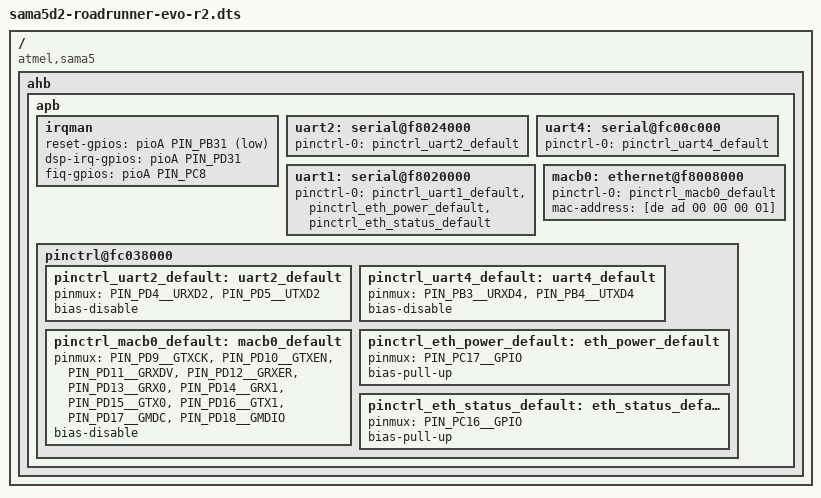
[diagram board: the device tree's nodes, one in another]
/dts-v1/;
/plugin/;

#include "../sama5d2-pinfunc.h"
#include <dt-bindings/gpio/gpio.h>

/ {
    fragment@011111 {
        target-path = "/";
        __overlay__ {
            compatible = "atmel,sama5", "atmel,sama5d2", "atmel,sama5d2-evo-r2";
            ahb {
                apb {
                    irqman: irqman {
                        reset-gpios     = <&pioA PIN_PB31 GPIO_ACTIVE_LOW>;  /* Reset on R2 is ACTIVE_LOW */
                        dsp-irq-gpios	= <&pioA PIN_PD31 GPIO_ACTIVE_HIGH>; /* EVO_IRQ0 */
                        fiq-gpios		= <&pioA PIN_PC8  GPIO_ACTIVE_HIGH>; /* EVO_FIQ  */
                    };

                    uart2: serial@f8024000 {
                        pinctrl-names = "default";
                        pinctrl-0 = <&pinctrl_uart2_default>;
                        status = "okay";
                    };

                    uart4: serial@fc00c000 {
                        pinctrl-names = "default";
                        pinctrl-0 = <&pinctrl_uart4_default>;
                        status = "okay";
                    };

                    uart1: serial@f8020000 {
                        pinctrl-names = "default";
                        /* pinctrl-0 = <&pinctrl_uart1_default>; */
                        pinctrl-0 = <&pinctrl_uart1_default
                                     &pinctrl_eth_power_default
                                     &pinctrl_eth_status_default>;
                        status = "okay";
                    };

                    macb0: ethernet@f8008000 {
                        pinctrl-names = "default";
                        pinctrl-0 = <&pinctrl_macb0_default>;
                        status = "okay";
                        mac-address = [de ad 00 00 00 01];
                    };

                    pinctrl@fc038000 {
                        pinctrl_uart2_default: uart2_default {
                            pinmux = <PIN_PD4__URXD2>,
                                 <PIN_PD5__UTXD2>;
                            bias-disable;
                        };

                        pinctrl_uart4_default: uart4_default {
                            pinmux = <PIN_PB3__URXD4>,
                                 <PIN_PB4__UTXD4>;
                            bias-disable;
                        };

                        pinctrl_macb0_default: macb0_default {
                            pinmux = <PIN_PD9__GTXCK>,
                                     <PIN_PD10__GTXEN>,
                                     <PIN_PD11__GRXDV>,
                                     <PIN_PD12__GRXER>,
                                     <PIN_PD13__GRX0>,
                                     <PIN_PD14__GRX1>,
                                     <PIN_PD15__GTX0>,
                                     <PIN_PD16__GTX1>,
                                     <PIN_PD17__GMDC>,
                                     <PIN_PD18__GMDIO>;
                            bias-disable;
                        };

                        pinctrl_eth_power_default: eth_power_default {
                            pinmux  = <PIN_PC17__GPIO>;
                            bias-pull-up;
                        };

                        pinctrl_eth_status_default: eth_status_default {
                            pinmux  = <PIN_PC16__GPIO>;
                            bias-pull-up;
                        };

                        /*
                        pinctrl_macb0_phy_irq: macb0_phy_irq {
                            pinmux = <PIN_PC9__GPIO>;
                            bias-disable;
                        };
                        */
                    };
                };
            };
        };
   };
};
